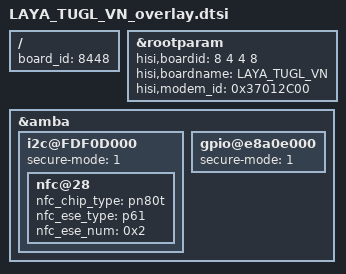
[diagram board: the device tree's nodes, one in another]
/**
 * Copyright (C) 2014 Hisilicon Ltd.
 *
 *  This program is free software; you can redistribute it and/or modify
 *  it under the terms of the GNU General Public License version 2 as
 *  publishhed by the Free Software Foundation.
 */

/include/ "LAYA_TUGL_VI_overlay.dtsi"

/ {
    board_id = <8448>;
};

	&rootparam{
		hisi,boardid = <8 4 4 8>;
		hisi,boardname = "LAYA_TUGL_VN";
		hisi,modem_id = <0x37012C00>;
	};

	&amba {
            i2c@FDF0D000 {
		secure-mode = <1>;
                    nfc@28{
                            nfc_chip_type = "pn80t";
                            nfc_ese_type = "p61";
			    nfc_ese_num = <0x2>;
                    };
            };
	    gpio@e8a0e000 {
		secure-mode = <1>;
	    };
    }; 
